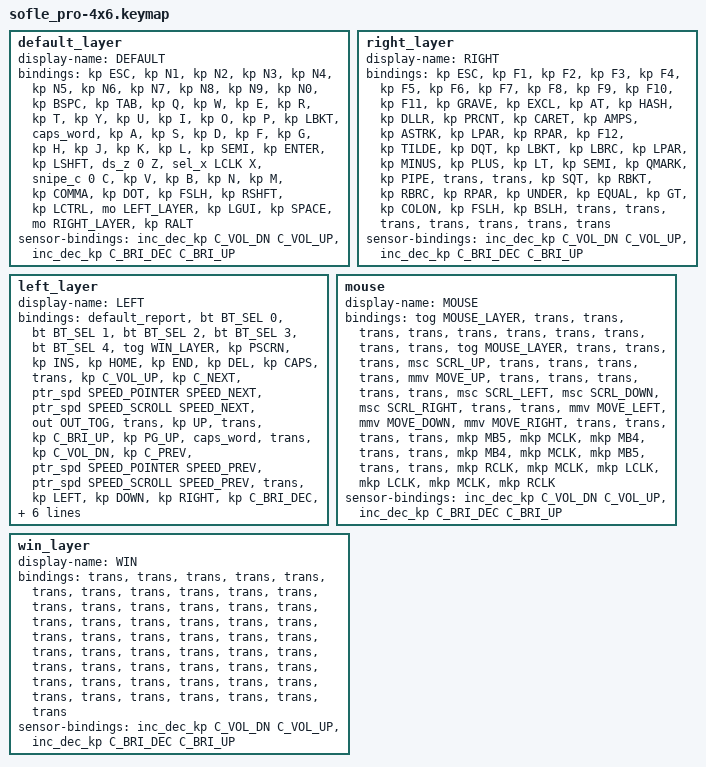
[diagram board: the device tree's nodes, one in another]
// Draft 4x6+3 layer set imported from the original stash.
// Integrate into config/sofle_pro.keymap after the Sofle-Pro matrix transform,
// pinout, and pointing behavior dependencies are finalized.

#define RIGHT_LAYER 1
#define LEFT_LAYER 2
#define MOUSE_LAYER 3
#define WIN_LAYER 4

#define SPEED_POINTER 0
#define SPEED_SCROLL 1
#define SPEED_PREV 0
#define SPEED_NEXT 1

// ------------------------------------------------------------------------------------------------------------
// |  ESC  |  1  |  2  |  3   |  4   |  5   |                   |  6   |  7    |  8    |  9   |   0   | BSPC  |
// |  TAB  |  Q  |  W  |  E   |  R   |  T   |                   |  Y   |  U    |  I    |  O   |   P   |   [   |
// |CAPS_WORD| A |  S  |  D   |  F   |  G   |                   |  H   |  J    |  K    |  L   |  ;:   | ENTER |
// | SHIFT |Z/DS |X/Sel|C/Snp |  V   |  B   |                   |  N   |  M    |  ,<   |  .>  |  /?   | SHIFT |
//                         | CTRL | LEFT | CMD |       | SPACE | RIGHT | OPT |
default_layer {
	display-name = "DEFAULT";
	bindings = <
	&kp ESC     &kp N1       &kp N2          &kp N3         &kp N4  &kp N5      &kp N6  &kp N7  &kp N8     &kp N9   &kp N0    &kp BSPC
	&kp TAB     &kp Q        &kp W           &kp E          &kp R   &kp T       &kp Y   &kp U   &kp I      &kp O    &kp P     &kp LBKT
	&caps_word  &kp A        &kp S           &kp D          &kp F   &kp G       &kp H   &kp J   &kp K      &kp L    &kp SEMI  &kp ENTER
	&kp LSHFT   &ds_z 0 Z    &sel_x LCLK X   &snipe_c 0 C   &kp V   &kp B       &kp N   &kp M   &kp COMMA  &kp DOT  &kp FSLH  &kp RSHFT
	                         &kp LCTRL       &mo LEFT_LAYER &kp LGUI       &kp SPACE  &mo RIGHT_LAYER  &kp RALT
	>;
	sensor-bindings = <&inc_dec_kp C_VOL_DN C_VOL_UP &inc_dec_kp C_BRI_DEC C_BRI_UP>;
};

// ------------------------------------------------------------------------------------------------------------
// |  ESC  |  F1 |  F2 |  F3  |  F4  |  F5  |                   |  F6  |  F7   |  F8   |  F9  |  F10  |  F11  |
// |   `   |  !  |  @  |  #   |  $   |  %   |                   |  ^   |  &    |  *    |  (   |   )   |  F12  |
// |   ~   |  "  |  [  |  {   |  (   |  -   |                   |  +   |  <    |  ;    |  ?   |   |   |       |
// |       |  '  |  ]  |  }   |  )   |  _   |                   |  =   |  >    |  :    |  /   |   \   |       |
//                         |      |      |      |       |       |       |
right_layer {
	display-name = "RIGHT";
	bindings = <
	&kp ESC    &kp F1    &kp F2    &kp F3    &kp F4    &kp F5       &kp F6     &kp F7    &kp F8    &kp F9    &kp F10   &kp F11
	&kp GRAVE  &kp EXCL  &kp AT    &kp HASH  &kp DLLR  &kp PRCNT    &kp CARET  &kp AMPS  &kp ASTRK &kp LPAR  &kp RPAR  &kp F12
	&kp TILDE  &kp DQT   &kp LBKT  &kp LBRC  &kp LPAR  &kp MINUS    &kp PLUS   &kp LT    &kp SEMI  &kp QMARK &kp PIPE  &trans
	&trans     &kp SQT   &kp RBKT  &kp RBRC  &kp RPAR  &kp UNDER    &kp EQUAL  &kp GT    &kp COLON &kp FSLH  &kp BSLH  &trans
	                     &trans    &trans    &trans       &trans     &trans    &trans
	>;
	sensor-bindings = <&inc_dec_kp C_VOL_DN C_VOL_UP &inc_dec_kp C_BRI_DEC C_BRI_UP>;
};

// ------------------------------------------------------------------------------------------------------------
// | REPORT|BT_SEL0|BT_SEL1|BT_SEL2 |BT_SEL3|BT_SEL4|                |TOG_WIN| PSCR |  INS | HOME |  END |  DEL |
// | CAPS  |       | VOL+ |  NEXT |  PTR+ | SCRL+ |                   |OUT_TOG|      |  UP  |      | BRI+ | PG_UP|
// |CAPS_WORD|     | VOL- |  PREV |  PTR- | SCRL- |                   |       | LEFT | DOWN | RIGHT| BRI- | PG_DN|
// |       |       | MUTE |  PLAY |       | BTCLR |                   |       |      |SOFT_OFF|    |      |      |
//                         |      |      | MENU |       |       |       |
left_layer {
	display-name = "LEFT";
	bindings = <
	&default_report  &bt BT_SEL 0  &bt BT_SEL 1  &bt BT_SEL 2  &bt BT_SEL 3                         &bt BT_SEL 4                         &tog WIN_LAYER  &kp PSCRN  &kp INS  &kp HOME  &kp END      &kp DEL
	&kp CAPS         &trans        &kp C_VOL_UP  &kp C_NEXT    &ptr_spd SPEED_POINTER SPEED_NEXT    &ptr_spd SPEED_SCROLL SPEED_NEXT     &out OUT_TOG    &trans     &kp UP   &trans    &kp C_BRI_UP &kp PG_UP
	&caps_word       &trans        &kp C_VOL_DN  &kp C_PREV    &ptr_spd SPEED_POINTER SPEED_PREV    &ptr_spd SPEED_SCROLL SPEED_PREV     &trans          &kp LEFT   &kp DOWN &kp RIGHT &kp C_BRI_DEC &kp PG_DN
	&trans           &trans        &kp C_MUTE    &kp C_PP      &trans                               &bt BT_CLR                           &trans          &trans     &soft_off &trans   &trans       &trans
	                                                           &trans                               &trans                               &kp K_APP       &trans     &trans   &trans
	>;
	sensor-bindings = <&inc_dec_kp C_VOL_DN C_VOL_UP &inc_dec_kp C_BRI_DEC C_BRI_UP>;
};

// ------------------------------------------------------------------------------------------------------------
// | MOUSE |       |       |       |       |       |                   |       |       |       |       |       | MOUSE |
// |       |       |       |SCRL_U |       |       |                   |       |       |MOV_UP |       |       |       |
// |       |       |SCRL_L |SCRL_D |SCRL_R |       |                   |       |MOV_L |MOV_D |MOV_R |       |       |
// |       |       |  MB5  | MCLK  |  MB4  |       |                   |       | MB4  | MCLK | MB5  |       |       |
//                         | RCLK | MCLK | LCLK |       | LCLK | MCLK | RCLK |
mouse {
	display-name = "MOUSE";
	bindings = <
	&tog MOUSE_LAYER  &trans  &trans           &trans           &trans            &trans      &trans  &trans          &trans          &trans          &trans  &tog MOUSE_LAYER
	&trans            &trans  &trans           &msc SCRL_UP     &trans            &trans      &trans  &trans          &mmv MOVE_UP    &trans          &trans  &trans
	&trans            &trans  &msc SCRL_LEFT   &msc SCRL_DOWN   &msc SCRL_RIGHT   &trans      &trans  &mmv MOVE_LEFT  &mmv MOVE_DOWN  &mmv MOVE_RIGHT &trans  &trans
	&trans            &trans  &mkp MB5         &mkp MCLK        &mkp MB4          &trans      &trans  &mkp MB4       &mkp MCLK       &mkp MB5        &trans  &trans
	                                   &mkp RCLK        &mkp MCLK        &mkp LCLK       &mkp LCLK       &mkp MCLK       &mkp RCLK
	>;
	sensor-bindings = <&inc_dec_kp C_VOL_DN C_VOL_UP &inc_dec_kp C_BRI_DEC C_BRI_UP>;
};

win_layer {
	display-name = "WIN";
	bindings = <
	&trans  &trans  &trans  &trans  &trans  &trans      &trans  &trans  &trans  &trans  &trans  &trans
	&trans  &trans  &trans  &trans  &trans  &trans      &trans  &trans  &trans  &trans  &trans  &trans
	&trans  &trans  &trans  &trans  &trans  &trans      &trans  &trans  &trans  &trans  &trans  &trans
	&trans  &trans  &trans  &trans  &trans  &trans      &trans  &trans  &trans  &trans  &trans  &trans
	                &trans  &trans  &trans      &trans  &trans  &trans
	>;
	sensor-bindings = <&inc_dec_kp C_VOL_DN C_VOL_UP &inc_dec_kp C_BRI_DEC C_BRI_UP>;
};
